VERSION ""

NS_ :

BS_:

BU_: XXX

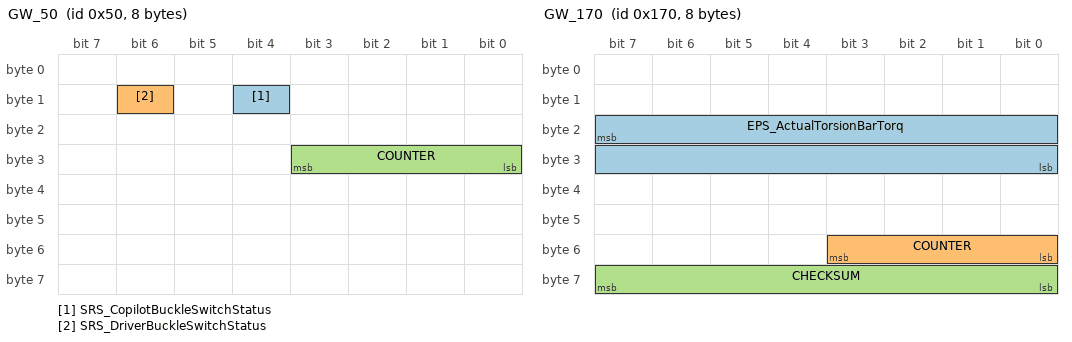
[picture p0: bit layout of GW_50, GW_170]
BO_ 80 GW_50: 8 XXX
 SG_ SRS_CopilotBuckleSwitchStatus : 12|1@0+ (1,0) [0|1] "" XXX
 SG_ SRS_DriverBuckleSwitchStatus : 14|1@0+ (1,0) [0|1] "" XXX
 SG_ COUNTER : 27|4@0+ (1,0) [0|15] "" XXX

BO_ 384 GW_180: 8 XXX
 SG_ SAS_SteeringAngle : 0|16@1- (0.1,1) [-476|476] "deg" XXX
 SG_ SAS_SteeringAngleSpeed : 16|8@0+ (1,0) [0|255] "" XXX
 SG_ COUNTER : 48|4@0+ (1,0) [0|15] "" XXX
 SG_ CHECKSUM : 63|8@0+ (1,0) [0|255] "" XXX

BO_ 391 GW_187: 8 XXX
 SG_ ESP_VehicleSpeed : 39|16@0+ (0.05,0) [0|255] "km/h" XXX
 SG_ COUNTER : 48|4@0+ (1,0) [0|15] "" XXX
 SG_ CHECKSUM : 63|8@0+ (1,0) [0|255] "" XXX

BO_ 424 GW_1A8: 8 XXX
 SG_ GearPosition : 8|4@1+ (1,0) [0|15] "" XXX
 SG_ COUNTER : 48|4@0+ (1,0) [0|15] "" XXX
 SG_ CHECKSUM : 63|8@0+ (1,0) [0|255] "" XXX

BO_ 518 GW_206: 8 XXX
 SG_ WheelSpeed_FR : 8|8@1+ (1,0) [0|255] "km/h" XXX
 SG_ WS_Standstill_FR : 6|1@0+ (1,0) [0|1] "" XXX
 SG_ WheelSpeed_FL : 24|8@1+ (1,0) [0|255] "km/h" XXX
 SG_ WS_Standstill_FL : 22|1@0+ (1,0) [0|1] "" XXX
 SG_ COUNTER : 48|4@0+ (1,0) [0|15] "" XXX
 SG_ CHECKSUM : 63|8@0+ (1,0) [0|255] "" XXX

BO_ 520 GW_208: 8 XXX
 SG_ WheelSpeed_RR : 8|8@1+ (1,0) [0|255] "km/h" XXX
 SG_ WS_Standstill_RR : 6|1@0+ (1,0) [0|1] "" XXX
 SG_ WheelSpeed_RL : 24|8@1+ (1,0) [0|255] "km/h" XXX
 SG_ WS_Standstill_RL : 22|1@0+ (1,0) [0|1] "" XXX
 SG_ COUNTER : 48|4@0+ (1,0) [0|15] "" XXX
 SG_ CHECKSUM : 63|8@0+ (1,0) [0|255] "" XXX

BO_ 618 GW_26A: 8 XXX
 SG_ EMS_AccelSwitch : 0|1@0+ (1,0) [0|1] "" XXX
 SG_ AcceleratorPedalPosition : 47|8@0+ (1,-31) [0|105] "%" XXX

BO_ 631 GW_277: 8 XXX
 SG_ ESP_BrakePedalStatus : 7|1@0+ (1,0) [0|1] "" XXX
 SG_ COUNTER : 48|4@0+ (1,0) [0|15] "" XXX
 SG_ CHECKSUM : 63|8@0+ (1,0) [0|255] "" XXX

BO_ 651 GW_28B: 8 XXX
 SG_ BCM_TurnIndicatorRight : 19|1@0+ (1,0) [0|1] "" XXX
 SG_ BCM_TurnIndicatorLeft : 21|1@0+ (1,0) [0|1] "" XXX
 SG_ BCM_DriverDoorStatus : 23|1@0+ (1,0) [0|1] "" XXX
 SG_ COUNTER : 48|4@0+ (1,0) [0|15] "" XXX
 SG_ CHECKSUM : 63|8@0+ (1,0) [0|255] "" XXX

BO_ 652 GW_28C: 8 XXX
 SG_ CruiseButton : 0|1@0+ (1,0) [0|1] "" XXX
 SG_ CruiseCancel : 2|1@0+ (1,0) [0|1] "" XXX
 SG_ CruiseResume : 4|1@0+ (1,0) [0|1] "" XXX
 SG_ CruiseSet : 6|1@0+ (1,0) [0|1] "" XXX
 SG_ IaccButton : 12|1@0+ (1,0) [0|1] "" XXX
 SG_ COUNTER : 48|4@0+ (1,0) [0|15] "" XXX
 SG_ CHECKSUM : 63|8@0+ (1,0) [0|255] "" XXX

BO_ 600 GW_258: 8 XXX
 SG_ GW258_Type M : 4|4@1+ (1,0) [0|15] "" XXX
 SG_ ESP_BrakePedalDepthLo m0 : 8|8@1+ (1,0) [0|255] "" XXX
 SG_ ESP_BrakePedalDepthHi m0 : 0|1@1+ (1,0) [0|1] "" XXX
 SG_ COUNTER m0 : 48|4@0+ (1,0) [0|15] "" XXX
 SG_ CHECKSUM m0 : 63|8@0+ (1,0) [0|255] "" XXX

BO_ 442 GW_1BA: 32 XXX
 SG_ ACC_MotorTorqueMinLimitRequest : 7|8@0+ (1,0) [0|255] "" XXX
 SG_ ACC_MotorTorqueMaxLimitRequest : 15|8@0+ (1,0) [0|255] "" XXX
 SG_ EPS_LatCtrlActive : 16|1@0+ (1,0) [0|1] "" XXX
 SG_ EPS_AngleCmd : 31|16@0- (0.1,0) [0|65535] "" XXX
 SG_ ACC_RollingCounter_1BA : 51|4@0+ (1,0) [0|15] "" XXX
 SG_ ACC_CRCCheck_1BA : 63|8@0+ (1,0) [0|255] "" XXX

BO_ 580 GW_244: 32 XXX
 SG_ ACC_ACCTargetAcceleration : 7|16@0- (0.001,-25.6) [-10|10] "m/s2" XXX
 SG_ ACC_AEBCtrlType : 34|3@0+ (1,0) [0|7] "" XXX
 SG_ ACC_FCWPreWarning : 35|1@0+ (1,0) [0|1] "" XXX
 SG_ ACC_AccTrqReqActive : 44|1@0+ (1,0) [0|1] "" XXX
 SG_ ACC_RollingCounter_24E : 51|4@0+ (1,0) [0|15] "" XXX
 SG_ ACC_ACCMode : 54|3@0+ (1,0) [0|7] "" XXX
 SG_ ACC_ACCReq : 55|1@0+ (1,0) [0|1] "" XXX
 SG_ ACC_CRCCheck_24E : 63|8@0+ (1,0) [0|255] "" XXX
 SG_ ACC_AccTrqReq : 103|16@0+ (1,0) [-32|32] "" XXX
 SG_ ACC_RollingCounter_25E : 115|4@0+ (1,0) [0|15] "" XXX
 SG_ ACC_CRCCheck_25E : 127|8@0+ (1,0) [0|255] "" XXX

BO_ 775 GW_307: 64 XXX
 SG_ ACC_SetSpeed : 7|16@0+ (0.0078125,0) [0|250] "km/h" XXX
 SG_ ACC_DistanceLevel : 17|2@0+ (1,0) [0|3] "" XXX
 SG_ ACC_RollingCounter_35E : 51|4@0+ (1,0) [0|15] "" XXX
 SG_ ACC_CRCCheck_35E : 63|8@0+ (1,0) [0|255] "" XXX
 SG_ ACC_RollingCounter_322 : 115|4@0+ (1,0) [0|15] "" XXX
 SG_ ACC_CRCCheck_322 : 127|8@0+ (1,0) [0|255] "" XXX
 SG_ ACC_RollingCounter_344 : 179|4@0+ (1,0) [0|15] "" XXX
 SG_ ACC_CRCCheck_344 : 191|8@0+ (1,0) [0|255] "" XXX
 SG_ ACC_RollingCounter_35F : 243|4@0+ (1,0) [0|15] "" XXX
 SG_ ACC_CRCCheck_35F : 255|8@0+ (1,0) [0|255] "" XXX

BO_ 794 GW_31A: 64 XXX
 SG_ ACC_RollingCounter_36D : 51|4@0+ (1,0) [0|15] "" XXX
 SG_ ACC_CRCCheck_36D : 63|8@0+ (1,0) [0|255] "" XXX
 SG_ ACC_IACCHWAEnable : 68|1@0+ (1,0) [0|1] "" XXX
 SG_ ACC_TargetBasedLateralControl : 96|1@0+ (1,0) [0|1] "" XXX
 SG_ ACC_RollingCounter_30A : 115|4@0+ (1,0) [0|15] "" XXX
 SG_ ACC_CRCCheck_30A : 127|8@0+ (1,0) [0|255] "" XXX
 SG_ ACC_IACCHWAMode : 135|3@0+ (1,0) [0|7] "" XXX
 SG_ ACC_RollingCounter_30D : 179|4@0+ (1,0) [0|15] "" XXX
 SG_ ACC_CRCCheck_30D : 191|8@0+ (1,0) [0|255] "" XXX
 SG_ ACC_RollingCounter_367 : 243|4@0+ (1,0) [0|15] "" XXX
 SG_ ACC_CRCCheck_367 : 255|8@0+ (1,0) [0|255] "" XXX

BO_ 368 GW_170: 8 ESP
 SG_ EPS_ActualTorsionBarTorq : 23|16@0+ (1,-5533) [0|65535] "" XXX
 SG_ COUNTER : 51|4@0+ (1,0) [0|15] "" XXX
 SG_ CHECKSUM : 63|8@0+ (1,0) [0|255] "" XXX

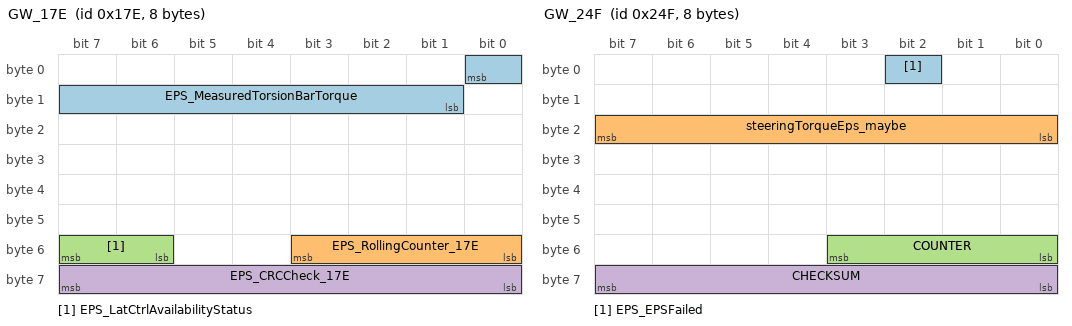
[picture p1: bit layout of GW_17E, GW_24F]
BO_ 382 GW_17E: 8 XXX
 SG_ EPS_MeasuredTorsionBarTorque : 0|8@0+ (1,-126) [-126|129] "Nm" XXX
 SG_ EPS_RollingCounter_17E : 51|4@0+ (1,0) [0|15] "" XXX
 SG_ EPS_LatCtrlAvailabilityStatus : 55|2@0+ (1,0) [0|3] "" XXX
 SG_ EPS_CRCCheck_17E : 63|8@0+ (1,0) [0|255] "" XXX

BO_ 591 GW_24F: 8 XXX
 SG_ EPS_EPSFailed : 2|1@0+ (1,0) [0|1] "" XXX
 SG_ steeringTorqueEps_maybe : 23|8@0- (0.1,0) [0|255] "" XXX
 SG_ COUNTER : 51|4@0+ (1,0) [0|15] "" XXX
 SG_ CHECKSUM : 63|8@0+ (1,0) [0|255] "" XXX

CM_ BO_ 384 "zhuanxiangjiao (steering angle, 0|16@0- yanzheng)";
CM_ SG_ 384 SAS_SteeringAngle "zhuanxiangjiao du (steering angle deg)";
CM_ SG_ 384 SAS_SteeringAngleSpeed "zhuanxiangjiao sudu (steering angle rate)";
CM_ BO_ 391 "chesu xinhao (vehicle speed, GW_187)";
CM_ SG_ 391 ESP_VehicleSpeed "chesu km/h (vehicle speed)";
CM_ BO_ 424 "dangwei (gear, 0x1A8 byte1 low nibble: 0x00=N, 0x01-0x07=1-7, 0x09=R, 0x0A=P)";
CM_ SG_ 424 GearPosition "dangwei";
CM_ BO_ 618 "youmen taban (accel pedal GW_26A)";
CM_ SG_ 618 EMS_AccelSwitch "youmen kaiguan byte0 bit0 (accel switch, 0=release 1=pressed)";
CM_ SG_ 618 AcceleratorPedalPosition "youmen kaidu % (accel pedal position, byte5 raw: 31=0%, 136=floor by accanjian.csv)";
CM_ BO_ 631 "shache taban (brake pedal GW_277)";
CM_ BO_ 651 "cheshen kongzhi BCM (body control: doors/turn signals)";
CM_ SG_ 651 BCM_TurnIndicatorRight "you zhuanxiang deng (right turn signal)";
CM_ SG_ 651 BCM_TurnIndicatorLeft "zuo zhuanxiang deng (left turn signal)";
CM_ BO_ 652 "fangxiangpan anjian (steering wheel buttons)";
CM_ SG_ 652 CruiseButton "dingsu";
CM_ SG_ 652 CruiseCancel "Exit_IACC";
CM_ SG_ 652 CruiseResume "RES+ anjian";
CM_ SG_ 652 CruiseSet "SET- anjian";
CM_ SG_ 652 IaccButton "IACC anjian";
CM_ BO_ 600 "shache taban shendu (brake pedal depth GW_258, muxed subframes)";
CM_ SG_ 600 GW258_Type "zizhen leixing (subframe type, byte0 high nibble: 0=pedal frame)";
CM_ SG_ 600 ESP_BrakePedalDepthLo "shache taban shendu di 8 wei (brake pedal depth low byte)";
CM_ SG_ 600 ESP_BrakePedalDepthHi "shache taban shendu di 9 wei (brake pedal depth bit8, value=Lo|Hi<<8, 500=100%)";
CM_ BO_ 442 "ADAS kongzhi mingling (ACC control command GW_1BA, 32 bytes)";
CM_ SG_ 442 EPS_LatCtrlActive "CESHI kongzhi jihuo (EPS lateral control active flag)";
CM_ SG_ 442 EPS_AngleCmd "CESHI jiaodu mingling (EPS angle command, 0.1 deg)";
CM_ BO_ 580 "ACC zhuangtai (ACC status GW_244, 32 bytes)";
CM_ SG_ 580 ACC_ACCTargetAcceleration "ACC mubiao jiasudu (ACC target acceleration m/s2, raw*0.001-25.6)";
CM_ SG_ 580 ACC_AEBCtrlType "AEB kongzhi leixing (AEB control type, 0=none)";
CM_ SG_ 580 ACC_FCWPreWarning "QZDY yujing (FCW pre-warning, 0=no 1=yes)";
CM_ SG_ 580 ACC_ACCMode "ACC moshi (ACC mode 54|3@0+, 2=standby 3=active 7=fault)";
CM_ SG_ 580 ACC_ACCReq "ACC qingqiu (ACC request, byte6 bit7)";
CM_ SG_ 580 ACC_AccTrqReq "ACC niuju qingqiu (ACC torque request, non-zero=active)";
CM_ BO_ 775 "ACC shezhi (ACC set speed/distance GW_307, 64 bytes, 4x16-byte sub-frames)";
CM_ SG_ 775 ACC_SetSpeed "ACC shezhi chesu (ACC set speed km/h, raw*0.0078125, verified 80.25/85.25/69.25)";
CM_ SG_ 775 ACC_DistanceLevel "ACC cheju dengji (ACC distance level, 0-3)";
CM_ BO_ 794 "IACC zhuangtai (IACC HWA status GW_31A, 64 bytes, 4x16-byte sub-frames)";
CM_ SG_ 794 ACC_IACCHWAEnable "IACC HWA keji (IACC HWA available, byte8 bit4, verified byte8=0x71->1)";
CM_ SG_ 794 ACC_IACCHWAMode "IACC HWA moshi (IACC HWA mode 135|3@0+, 7=fault)";
CM_ SG_ 794 ACC_TargetBasedLateralControl "HCEngji mubiao hengxiang kongzhi (HWA target-based lateral control, byte12 bit0)";
CM_ BO_ 368 "EPS shiji niuju (EPS actual torsion bar torque GW_170, byte2-3, dai yanzheng)";
CM_ SG_ 368 EPS_ActualTorsionBarTorq "EPS shiji niuju (actual torsion bar torque, 23|16@0+ (1,-5533), dai yanzheng: 01.csv zhong byte2-3 bu lianxu, byte3 zhiyou 22 distinct zhi, kending yichang)";
CM_ BO_ 382 "EPS celiang niuju (EPS measured torsion bar torque GW_17E, byte0)";
CM_ SG_ 382 EPS_MeasuredTorsionBarTorque "jiashiyuan niuju (driver torque Nm, byte0 wufuhao + offset -126, 01.csv yanzheng: zhixing fenbu 0x7E=126 fengzhi, fanwei 81~220 -> -45~+94 Nm, jiu dingyi 7|12@0- cuowu)";
CM_ SG_ 382 EPS_LatCtrlAvailabilityStatus "CESHI hengxiang kongzhi keji zhuangtai (EPS lat ctrl availability, byte6 bits7,6, 01.csv zhiqu {0,1}, 0=83% 1=17%)";
CM_ BO_ 591 "EPS guzhuang (EPS fault GW_24F, 8 bytes)";
CM_ SG_ 591 EPS_EPSFailed "EPS guzhuang (EPS failed, byte0 bit2, WUDINGYI: byte0 shi fuzhi xinhao jingzhi=1 kuaizhuan=43, zhengchang kuaiman zhuanxiang shi wuchufa 2%)";
CM_ SG_ 591 steeringTorqueEps_maybe "EPS niuju yubei (EPS torque maybe, byte2 youfuhao 0.1, 01.csv 127 wei zhongxin, yu 0x17E byte0 danziangliang)";
VAL_ 80 SRS_CopilotBuckleSwitchStatus 0 "close" 1 "open";
VAL_ 80 SRS_DriverBuckleSwitchStatus 0 "close" 1 "open";
VAL_ 424 GearPosition 0 "N" 1 "D1" 2 "2" 3 "3" 4 "4" 5 "5" 6 "6" 7 "7" 9 "R" 10 "P";
VAL_ 618 EMS_AccelSwitch 0 "release" 1 "pressed";
VAL_ 631 ESP_BrakePedalStatus 0 "release" 1 "pressed";
VAL_ 651 BCM_TurnIndicatorRight 0 "no" 1 "turn_right";
VAL_ 651 BCM_TurnIndicatorLeft 0 "no" 1 "turn_left";
VAL_ 651 BCM_DriverDoorStatus 0 "close" 1 "open";
VAL_ 652 CruiseButton 0 "no" 1 "Press";
VAL_ 652 CruiseCancel 0 "no" 1 "Press";
VAL_ 652 CruiseResume 0 "no" 1 "reset/+";
VAL_ 652 CruiseSet 0 "no" 1 "set-";
VAL_ 652 IaccButton 0 "no" 1 "On_IACC";
VAL_ 600 GW258_Type 0 "PedalFrame";
VAL_ 442 EPS_LatCtrlActive 0 "inactive" 1 "active";
VAL_ 580 ACC_AEBCtrlType 0 "none" 1 "active";
VAL_ 580 ACC_FCWPreWarning 0 "no" 1 "yes";
VAL_ 580 ACC_ACCMode 0 "off" 1 "inactive" 2 "standby" 3 "active" 7 "fault";
VAL_ 580 ACC_ACCReq 0 "no" 1 "yes";
VAL_ 580 ACC_AccTrqReqActive 0 "no" 1 "yes";
VAL_ 794 ACC_IACCHWAEnable 0 "no" 1 "yes";
VAL_ 794 ACC_TargetBasedLateralControl 0 "no" 1 "yes";
VAL_ 794 ACC_IACCHWAMode 0 "off" 7 "fault";
VAL_ 382 EPS_LatCtrlAvailabilityStatus 0 "available" 1 "unavailable";
VAL_ 591 EPS_EPSFailed 0 "no" 1 "yes";
